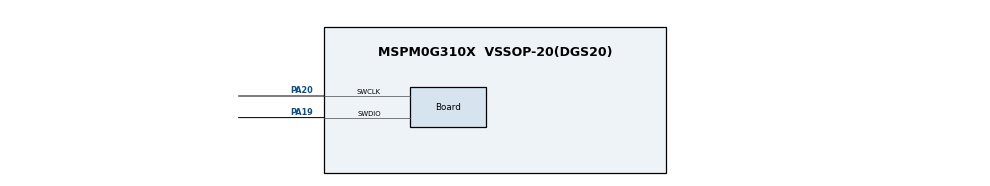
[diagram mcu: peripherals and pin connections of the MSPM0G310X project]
/**
 * @cliArgs --device "MSPM0G310X" --part "Default" --package "VSSOP-20(DGS20)" --product "mspm0_sdk@2.04.00.06"
 * @versions {"tool":"1.23.0+4000"}
 */

/**
 * Import the modules used in this configuration.
 */
const GPIO          = scripting.addModule("/ti/driverlib/GPIO", {}, false);
const GPIO1         = GPIO.addInstance();
const SYSCTL        = scripting.addModule("/ti/driverlib/SYSCTL");
const ProjectConfig = scripting.addModule("/ti/project_config/ProjectConfig");

/**
 * Write custom configuration values to the imported modules.
 */
GPIO1.$name                              = "LED1";
GPIO1.associatedPins[0].internalResistor = "PULL_DOWN";
GPIO1.associatedPins[0].$name            = "PIN_1";

const Board                       = scripting.addModule("/ti/driverlib/Board", {}, false);
Board.peripheral.$assign          = "DEBUGSS";
Board.peripheral.swclkPin.$assign = "PA20";
Board.peripheral.swdioPin.$assign = "PA19";

SYSCTL.peripheral.$assign = "SYSCTL";

ProjectConfig.migrationCondition = true;

/**
 * Pinmux solution for unlocked pins/peripherals. This ensures that minor changes to the automatic solver in a future
 * version of the tool will not impact the pinmux you originally saw.  These lines can be completely deleted in order to
 * re-solve from scratch.
 */
GPIO1.associatedPins[0].pin.$suggestSolution = "PA26";
